# LPC55S16 register map
Vendor: nxp.com; File version: 1.0
CPU: CM33 r2p0, little endian, MPU, FPU, VTOR, 3 interrupt priority bits
Registers are 32-bit, read-write, reset 0x0 unless marked. A register's access mark holds for its fields unless they carry their own. Offsets are from the block's base; [hi:lo] are bit positions; {n}, {i} and the like mark numbered series.

## PRINCE
Base 0x40035000
0x00 ENC_ENABLE — Encryption Enable register
  [0] EN — Enables PRINCE encryption for flash programming.
    0=DISABLED (Encryption of writes to the flash controller DATAW* registers is disabled.); 1=ENABLED (Encryption of writes to the flash controller DATAW* registers is enabled. Reading of PRINCE-encrypted flash regions is disabled.)
0x04 MASK_LSB wo — Data Mask register, 32 Least Significant Bits
  [31:0] MASKVAL — Value of the 32 Least Significant Bits of the 64-bit data mask.
0x08 MASK_MSB wo — Data Mask register, 32 Most Significant Bits
  [31:0] MASKVAL — Value of the 32 Most Significant Bits of the 64-bit data mask.
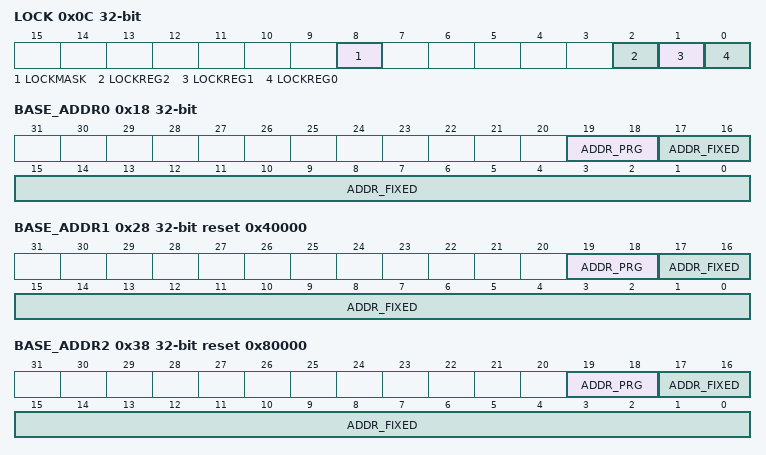
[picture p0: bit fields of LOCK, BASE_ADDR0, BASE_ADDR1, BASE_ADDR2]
0x0C LOCK
  [8] LOCKMASK — Lock the Mask registers.
    0=DISABLED (Disabled. MASK_LSB, and MASK_MSB are writable..); 1=ENABLED (Enabled. MASK_LSB, and MASK_MSB are not writable..)
  [2] LOCKREG2 — Lock Region 2 registers.
    0=DISABLED (Disabled. IV_LSB2, IV_MSB2, BASE_ADDR2, and SR_ENABLE2 are writable..); 1=ENABLED (Enabled. IV_LSB2, IV_MSB2, BASE_ADDR2, and SR_ENABLE2 are not writable..)
  [1] LOCKREG1 — Lock Region 1 registers.
    0=DISABLED (Disabled. IV_LSB1, IV_MSB1, BASE_ADDR1, and SR_ENABLE1 are writable..); 1=ENABLED (Enabled. IV_LSB1, IV_MSB1, BASE_ADDR1, and SR_ENABLE1 are not writable..)
  [0] LOCKREG0 — Lock Region 0 registers.
    0=DISABLED (Disabled. IV_LSB0, IV_MSB0, BASE_ADDR0, and SR_ENABLE0 are writable..); 1=ENABLED (Enabled. IV_LSB0, IV_MSB0, BASE_ADDR0, and SR_ENABLE0 are not writable..)
{0x10+0x10*i} IV_LSB{i} wo (i=0..2) — Initial Vector register for region {i}, Least Significant Bits
  [31:0] IVVAL — Initial Vector value for the 32 Least Significant Bits of the 64-bit Initial Vector.
{0x14+0x10*i} IV_MSB{i} wo (i=0..2) — Initial Vector register for region {i}, Most Significant Bits
  [31:0] IVVAL — Initial Vector value for the 32 Most Significant Bits of the 64-bit Initial Vector.
0x18 BASE_ADDR0 — Base Address for region 0 register
  [19:18] ADDR_PRG — Programmable portion of the base address of region 0.
  [17:0] ADDR_FIXED ro — Fixed portion of the base address of region 0.
{0x1C+0x10*i} SR_ENABLE{i} (i=0..2) — Sub-Region Enable register for region {i}
  [31:0] EN — Each bit in this field enables an 8KB subregion for encryption at offset 8KB*bitnum of region {i}.
0x28 BASE_ADDR1 reset 0x40000 — Base Address for region 1 register
  [19:18] ADDR_PRG — Programmable portion of the base address of region 1.
  [17:0] ADDR_FIXED ro — Fixed portion of the base address of region 1.
0x38 BASE_ADDR2 reset 0x80000 — Base Address for region 2 register
  [19:18] ADDR_PRG — Programmable portion of the base address of region 2.
  [17:0] ADDR_FIXED ro — Fixed portion of the base address of region 2.
0x90 ERR — Error status register
  [0] ERRSTAT — PRINCE Error Status. This bit is write-1 to clear.
    0=NO_ERROR (No PRINCE error.); 1=ERROR (Error. A read of a PRINCE-encrypted region was attempted while ENC_ENABLE.EN=1.)

## RNG
Base 0x4003A000
0x00 RANDOM_NUMBER ro — This register contains a random 32 bit number which is computed on demand, at each time it is read
  [31:0] RANDOM_NUMBER — This register contains a random 32 bit number which is computed on demand, at each time it is read.
0x04 ENCRYPTED_NUMBER ro — This register contains a random 32 bit number which is pre-computed
  [31:0] ENCRYPTED_NUMBER — This register contains a random 32 bit number which is pre-computed.
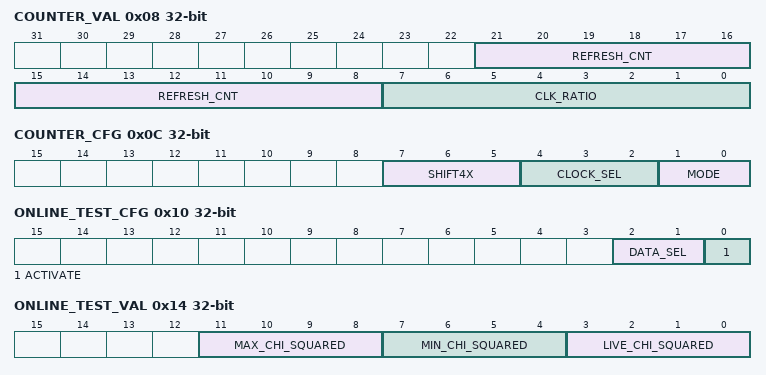
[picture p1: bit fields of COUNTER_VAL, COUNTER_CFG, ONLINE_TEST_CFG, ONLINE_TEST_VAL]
0x08 COUNTER_VAL (reset mask 0x1FFF)
  [21:8] REFRESH_CNT ro — Incremented (till max possible value) each time COUNTER was updated since last reading to any *_NUMBER.
  [7:0] CLK_RATIO ro — Gives the ratio between the internal clocks frequencies and the register clock frequency for evaluation and certification purposes.
0x0C COUNTER_CFG
  [7:5] SHIFT4X — To be used to add precision to clock_ratio and determine 'entropy refill'.
  [4:2] CLOCK_SEL — Selects the internal clock on which to compute statistics.
  [1:0] MODE — 00: disabled 01: update once.
0x10 ONLINE_TEST_CFG
  [2:1] DATA_SEL — Selects source on which to apply online test: 00: LSB of COUNTER: raw data from one or all sources of entropy 01: MSB of COUNTER: raw data from one or all sources of entropy 10: RANDOM_NUMBER 11: ENCRYPTED_NUMBER 'activate' should be set to 'disabled' before changing this field.
  [0] ACTIVATE — 0: disabled 1: activated Update rythm for VAL depends on COUNTER_CFG if data_sel is set to COUNTER.
0x14 ONLINE_TEST_VAL
  [11:8] MAX_CHI_SQUARED ro — This field is reset when 'activate'==0.
  [7:4] MIN_CHI_SQUARED ro — This field is reset when 'activate'==0.
  [3:0] LIVE_CHI_SQUARED ro — This value is updated as described in field 'activate'.
0x18 ENTROPY_INJECT (reset mask 0x3)
  [31:0] ENTROPY — Use this register to inject or restore entropy 32 bits at a time. Writing is blocking thus see to it to have analog clocks activated. Injection can be usefull to add contribution from an external source of entropy, like for example LSBs of an ADC or of a temperature sensor. Restore can be usefull to store N random numbers in central memory before going powerdown then restore this entropy to RNG IP after power-up. It is useless to inject or restore more than 1*(number of RNGs) 32b words consecutively. Recommendation is to inject 1*(number of RNGs) words, and possibly later (2*32 clock cycles of slowest analog clock) inject again 1*(number of RNGs) words. Then maximum capacity of restoration is reached: about 44 bits per RNG (not to be mistaken with maximum capacity of entropy accumulation which is about 100 bits per RNG). You can inject less than 32 bits words (let unused bits to 0). Injection cannot degrade overall performance due to the fact that some internal PRNGs are excluded on purpose from this external action.
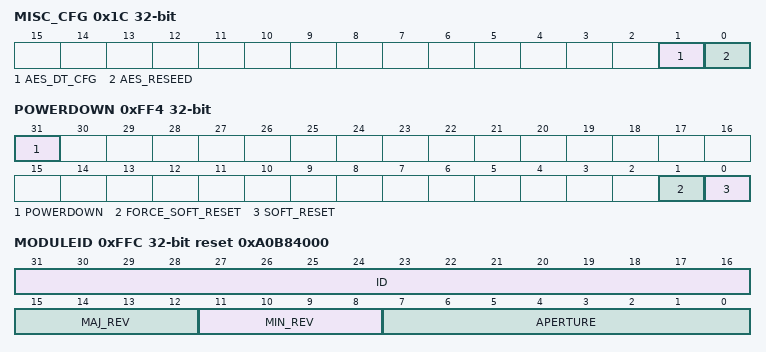
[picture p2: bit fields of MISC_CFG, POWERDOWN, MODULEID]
0x1C MISC_CFG
  [1] AES_DT_CFG — Set this bit to re-seed AES.
  [0] AES_RESEED — If set, ENCRYPTED_NUMBER generation becomes predictable, provided all secrets and current internal state are known: independant from entropy source.
0xFF4 POWERDOWN — Powerdown mode (standard but certainly useless here)
  [31] POWERDOWN — When set all accesses to standard registers are blocked.
  [1] FORCE_SOFT_RESET — When used with softreset it forces CORE_RESETN to low on acknowledge from CORE.
  [0] SOFT_RESET — Request softreset that will go low automaticaly after acknowledge from CORE.
0xFFC MODULEID ro reset 0xA0B84000 — IP identifier
  [31:16] ID — Identifier.
  [15:12] MAJ_REV — Major revision i.
  [11:8] MIN_REV — Minor revision i.
  [7:0] APERTURE — Aperture i.
